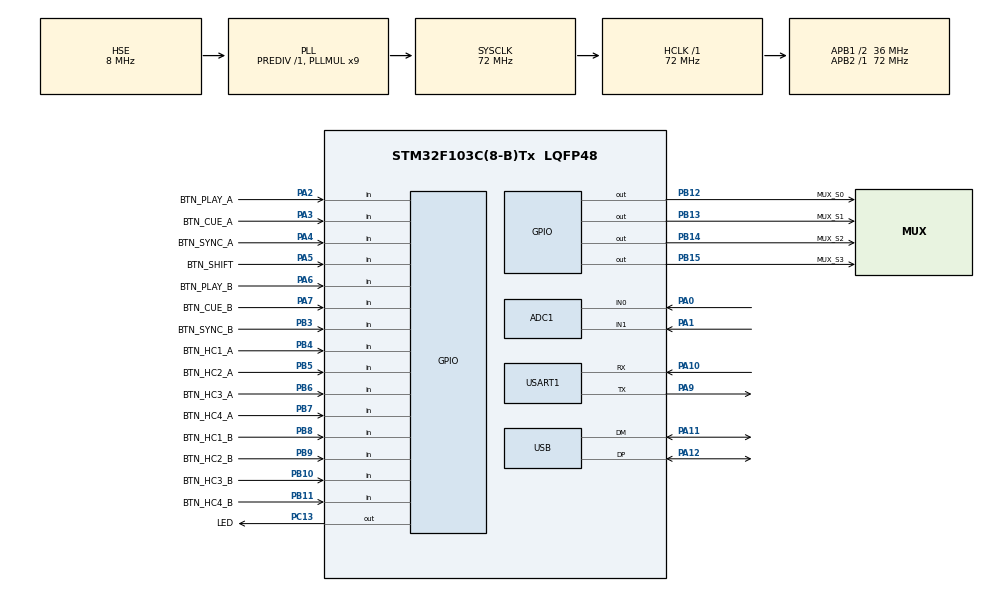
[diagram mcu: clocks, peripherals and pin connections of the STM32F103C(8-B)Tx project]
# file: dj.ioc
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ADC1.Channel-0\#ChannelRegularConversion=ADC_CHANNEL_0
ADC1.NbrOfConversionFlag=1
ADC1.Rank-0\#ChannelRegularConversion=1
ADC1.SamplingTime-0\#ChannelRegularConversion=ADC_SAMPLETIME_71CYCLES_5
ADC1.master=1
FREERTOS.Tasks01=led,24,128,led_task,As weak,NULL,Dynamic,NULL,NULL
FREERTOS.configCHECK_FOR_STACK_OVERFLOW=2
FREERTOS.configTOTAL_HEAP_SIZE=8192
FREERTOS.configUSE_MALLOC_FAILED_HOOK=1
FREERTOS.configUSE_NEWLIB_REENTRANT=0
Mcu.Family=STM32F1
Mcu.Name=STM32F103C(8-B)Tx
Mcu.Package=LQFP48
NVIC.PriorityGroup=NVIC_PRIORITYGROUP_4
NVIC.TIM4_IRQn=true\:15\:0\:false\:false\:true\:false\:false\:true\:true
NVIC.TimeBase=TIM4_IRQn
NVIC.TimeBaseIP=TIM4
PA0-WKUP.Signal=ADCx_IN0
PA1.Signal=ADCx_IN1
PA10.Mode=Asynchronous
PA10.Signal=USART1_RX
PA11.Mode=Device
PA11.Signal=USB_DM
PA12.Mode=Device
PA12.Signal=USB_DP
PA13.Mode=Serial_Wire
PA13.Signal=SYS_JTMS-SWDIO
PA14.Mode=Serial_Wire
PA14.Signal=SYS_JTCK-SWCLK
PA2.GPIO_Label=BTN_PLAY_A
PA2.GPIO_PuPd=GPIO_PULLUP
PA2.Signal=GPIO_Input
PA3.GPIO_Label=BTN_CUE_A
PA3.GPIO_PuPd=GPIO_PULLUP
PA3.Signal=GPIO_Input
PA4.GPIO_Label=BTN_SYNC_A
PA4.GPIO_PuPd=GPIO_PULLUP
PA4.Signal=GPIO_Input
PA5.GPIO_Label=BTN_SHIFT
PA5.GPIO_PuPd=GPIO_PULLUP
PA5.Signal=GPIO_Input
PA6.GPIO_Label=BTN_PLAY_B
PA6.GPIO_PuPd=GPIO_PULLUP
PA6.Signal=GPIO_Input
PA7.GPIO_Label=BTN_CUE_B
PA7.GPIO_PuPd=GPIO_PULLUP
PA7.Signal=GPIO_Input
PA9.Mode=Asynchronous
PA9.Signal=USART1_TX
PB10.GPIO_Label=BTN_HC3_B
PB10.GPIO_PuPd=GPIO_PULLUP
PB10.Signal=GPIO_Input
PB11.GPIO_Label=BTN_HC4_B
PB11.GPIO_PuPd=GPIO_PULLUP
PB11.Signal=GPIO_Input
PB12.GPIO_Label=MUX_S0
PB12.Signal=GPIO_Output
PB13.GPIO_Label=MUX_S1
PB13.GPIO_Speed=GPIO_SPEED_FREQ_LOW
PB13.Signal=GPIO_Output
PB14.GPIO_Label=MUX_S2
PB14.GPIO_Speed=GPIO_SPEED_FREQ_LOW
PB14.Signal=GPIO_Output
PB15.GPIO_Label=MUX_S3
PB15.GPIO_Speed=GPIO_SPEED_FREQ_LOW
PB15.Signal=GPIO_Output
PB3.GPIO_Label=BTN_SYNC_B
PB3.GPIO_PuPd=GPIO_PULLUP
PB3.Signal=GPIO_Input
PB4.GPIO_Label=BTN_HC1_A
PB4.GPIO_PuPd=GPIO_PULLUP
PB4.Signal=GPIO_Input
PB5.GPIO_Label=BTN_HC2_A
PB5.GPIO_PuPd=GPIO_PULLUP
PB5.Signal=GPIO_Input
PB6.GPIO_Label=BTN_HC3_A
PB6.GPIO_PuPd=GPIO_PULLUP
PB6.Signal=GPIO_Input
PB7.GPIO_Label=BTN_HC4_A
PB7.GPIO_PuPd=GPIO_PULLUP
PB7.Signal=GPIO_Input
PB8.GPIO_Label=BTN_HC1_B
PB8.GPIO_PuPd=GPIO_PULLUP
PB8.Signal=GPIO_Input
PB9.GPIO_Label=BTN_HC2_B
PB9.GPIO_PuPd=GPIO_PULLUP
PB9.Signal=GPIO_Input
PC13-TAMPER-RTC.GPIO_Label=LED
PC13-TAMPER-RTC.PinState=GPIO_PIN_SET
PC13-TAMPER-RTC.Signal=GPIO_Output
PD0-OSC_IN.Mode=HSE-External-Oscillator
PD0-OSC_IN.Signal=RCC_OSC_IN
PD1-OSC_OUT.Mode=HSE-External-Oscillator
PD1-OSC_OUT.Signal=RCC_OSC_OUT
ProjectManager.HeapSize=0x200
ProjectManager.StackSize=0x400
ProjectManager.TargetToolchain=CMake
RCC.ADCPresc=RCC_ADCPCLK2_DIV6
RCC.AHBFreq_Value=72000000
RCC.APB1CLKDivider=RCC_HCLK_DIV2
RCC.APB1Freq_Value=36000000
RCC.APB1TimFreq_Value=72000000
RCC.APB2Freq_Value=72000000
RCC.APB2TimFreq_Value=72000000
RCC.HCLKFreq_Value=72000000
RCC.PLLMUL=RCC_PLL_MUL9
RCC.SYSCLKFreq_VALUE=72000000
RCC.SYSCLKSource=RCC_SYSCLKSOURCE_PLLCLK
RCC.USBFreq_Value=48000000
RCC.USBPrescaler=RCC_USBCLKSOURCE_PLL_DIV1_5
SH.ADCx_IN0.0=ADC1_IN0,IN0
SH.ADCx_IN1.0=ADC1_IN1,IN1
USART1.VirtualMode=VM_ASYNC
VP_FREERTOS_VS_CMSIS_V2.Mode=CMSIS_V2
VP_SYS_VS_tim4.Mode=TIM4
board=custom

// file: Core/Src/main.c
/* USER CODE BEGIN Header */
/**
  ******************************************************************************
  * @file           : main.c
  * @brief          : Main program body
  ******************************************************************************
  * @attention
  *
  * Copyright (c) 2026 STMicroelectronics.
  * All rights reserved.
  *
  * This software is licensed under terms that can be found in the LICENSE file
  * in the root directory of this software component.
  * If no LICENSE file comes with this software, it is provided AS-IS.
  *
  ******************************************************************************
  */
/* USER CODE END Header */
#include "main.h"
#include "cmsis_os.h"
#include "adc.h"
#include "usart.h"
#include "usb.h"
#include "gpio.h"

/* USER CODE BEGIN Includes */
#include <stdio.h>
/* USER CODE END Includes */

void SystemClock_Config(void);
void MX_FREERTOS_Init(void);

int main(void)
{

  /* MCU Configuration--------------------------------------------------------*/

  /* Reset of all peripherals, Initializes the Flash interface and the Systick. */
  HAL_Init();

  /* Configure the system clock */
  SystemClock_Config();

  /* Initialize all configured peripherals */
  MX_GPIO_Init();
  MX_USART1_UART_Init();
  MX_ADC1_Init();
  /* USER CODE BEGIN 2 */
  /* Debug UART (USART1, PA9 TX) is up from here on, see debug_uart.c */
  printf("dj controller boot, SYSCLK = %lu Hz\n", HAL_RCC_GetSysClockFreq());
  /* USER CODE END 2 */

  /* Init scheduler */
  osKernelInitialize();  /* Call init function for freertos objects (in cmsis_os2.c) */
  MX_FREERTOS_Init();

  /* Start scheduler */
  osKernelStart();

  /* We should never get here as control is now taken by the scheduler */

  /* Infinite loop */
  while (1)
  {

  }
}

void SystemClock_Config(void)
{
  RCC_OscInitTypeDef RCC_OscInitStruct = {0};
  RCC_ClkInitTypeDef RCC_ClkInitStruct = {0};
  RCC_PeriphCLKInitTypeDef PeriphClkInit = {0};

  /** Initializes the RCC Oscillators according to the specified parameters
  * in the RCC_OscInitTypeDef structure.
  */
  RCC_OscInitStruct.OscillatorType = RCC_OSCILLATORTYPE_HSE;
  RCC_OscInitStruct.HSEState = RCC_HSE_ON;
  RCC_OscInitStruct.HSEPredivValue = RCC_HSE_PREDIV_DIV1;
  RCC_OscInitStruct.HSIState = RCC_HSI_ON;
  RCC_OscInitStruct.PLL.PLLState = RCC_PLL_ON;
  RCC_OscInitStruct.PLL.PLLSource = RCC_PLLSOURCE_HSE;
  RCC_OscInitStruct.PLL.PLLMUL = RCC_PLL_MUL9;
  if (HAL_RCC_OscConfig(&RCC_OscInitStruct) != HAL_OK)
  {
    Error_Handler();
  }

  /** Initializes the CPU, AHB and APB buses clocks
  */
  RCC_ClkInitStruct.ClockType = RCC_CLOCKTYPE_HCLK|RCC_CLOCKTYPE_SYSCLK
                              |RCC_CLOCKTYPE_PCLK1|RCC_CLOCKTYPE_PCLK2;
  RCC_ClkInitStruct.SYSCLKSource = RCC_SYSCLKSOURCE_PLLCLK;
  RCC_ClkInitStruct.AHBCLKDivider = RCC_SYSCLK_DIV1;
  RCC_ClkInitStruct.APB1CLKDivider = RCC_HCLK_DIV2;
  RCC_ClkInitStruct.APB2CLKDivider = RCC_HCLK_DIV1;

  if (HAL_RCC_ClockConfig(&RCC_ClkInitStruct, FLASH_LATENCY_2) != HAL_OK)
  {
    Error_Handler();
  }
  PeriphClkInit.PeriphClockSelection = RCC_PERIPHCLK_ADC|RCC_PERIPHCLK_USB;
  PeriphClkInit.AdcClockSelection = RCC_ADCPCLK2_DIV6;
  PeriphClkInit.UsbClockSelection = RCC_USBCLKSOURCE_PLL_DIV1_5;
  if (HAL_RCCEx_PeriphCLKConfig(&PeriphClkInit) != HAL_OK)
  {
    Error_Handler();
  }
}

void HAL_TIM_PeriodElapsedCallback(TIM_HandleTypeDef *htim)
{
  if (htim->Instance == TIM4)
  {
    HAL_IncTick();
  }
}

void Error_Handler(void)
{
  __disable_irq();
  while (1)
  {
  }
}

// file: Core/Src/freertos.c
/* USER CODE BEGIN Header */
/**
  ******************************************************************************
  * File Name          : freertos.c
  * Description        : Code for freertos applications
  ******************************************************************************
  * @attention
  *
  * Copyright (c) 2026 STMicroelectronics.
  * All rights reserved.
  *
  * This software is licensed under terms that can be found in the LICENSE file
  * in the root directory of this software component.
  * If no LICENSE file comes with this software, it is provided AS-IS.
  *
  ******************************************************************************
  */
/* USER CODE END Header */

#include "FreeRTOS.h"
#include "task.h"
#include "main.h"
#include "cmsis_os.h"

/* USER CODE BEGIN Includes */
#include "app_tasks.h"
#include "debug_uart.h"
/* USER CODE END Includes */

/* Definitions for led */
osThreadId_t ledHandle;
const osThreadAttr_t led_attributes = {
  .name = "led",
  .stack_size = 128 * 4,
  .priority = (osPriority_t) osPriorityNormal,
};

void led_task(void *argument);

void MX_FREERTOS_Init(void); /* (MISRA C 2004 rule 8.1) */

/* Hook prototypes */
void vApplicationStackOverflowHook(xTaskHandle xTask, signed char *pcTaskName);
void vApplicationMallocFailedHook(void);

/* USER CODE BEGIN 4 */
void vApplicationStackOverflowHook(xTaskHandle xTask, signed char *pcTaskName)
{
  /* Called by the kernel during a context switch (interrupt context) when a
   * task has written past the end of its stack. Memory may already be
   * corrupted, so: interrupts off, raw UART print, stop. Fix: raise the
   * stack size of the named task in app_tasks.c. */
  (void)xTask;
  __disable_irq();
  debug_uart_puts_unlocked("\r\n*** FreeRTOS: stack overflow in task '");
  debug_uart_puts_unlocked((const char *)pcTaskName);
  debug_uart_puts_unlocked("'\r\n");
  Error_Handler();
}
/* USER CODE END 4 */

/* USER CODE BEGIN 5 */
void vApplicationMallocFailedHook(void)
{
  /* Called when pvPortMalloc() fails: the FreeRTOS heap (configTOTAL_HEAP_SIZE
   * in FreeRTOSConfig.h, set in CubeMX) is too small for the tasks, queues and
   * mutexes being created. Fix: raise TOTAL_HEAP_SIZE or shrink task stacks. */
  __disable_irq();
  debug_uart_puts_unlocked("\r\n*** FreeRTOS: out of heap (TOTAL_HEAP_SIZE)\r\n");
  Error_Handler();
}
/* USER CODE END 5 */

void MX_FREERTOS_Init(void) {

  /* USER CODE BEGIN RTOS_MUTEX */
  /* printf() lock for USART1, must exist before any task can print */
  debug_uart_init();
  /* USER CODE END RTOS_MUTEX */

  /* Create the thread(s) */
  /* creation of led */
  ledHandle = osThreadNew(led_task, NULL, &led_attributes);

  /* USER CODE BEGIN RTOS_THREADS */
  app_tasks_create();
  /* USER CODE END RTOS_THREADS */

}

__weak void led_task(void *argument)
{
  for(;;)
  {
    osDelay(1);
  }
}
